# adcss_ADC_20608000h register map
Vendor: Texas Instruments
Peripheral module from a debugger description file (folder AM275x).
Registers are 32-bit, read-only, reset 0x0 unless marked. A register's access mark holds for its fields unless they carry their own. Offsets are as the file gives them; lines under a group give offsets from that group; [hi:lo] are bit positions; {n}, {i} and the like mark numbered series; 'fields as' and 'values as' point back to an identical list; <NAME> marks a mode.

## adc
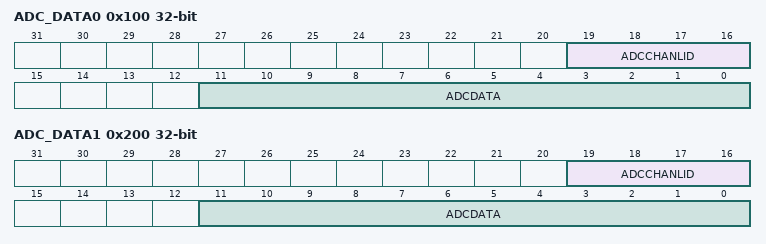
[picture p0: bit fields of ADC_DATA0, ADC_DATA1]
0x100 ADC_DATA0 — DMA sample FIFO
  [19:16] ADCCHANLID — Optional ID tag of channel that captured the data.If tag option is disabled, these bits will be 0 Reset Source: rst_mod_g_rst_n
  [11:0] ADCDATA — sampled ADC converted data value stored in FIFO Reset Source: rst_mod_g_rst_n
0x200 ADC_DATA1 — DMA sample FIFO
  fields as ADC_DATA0
